# FM33LG0XX register map
File version: 1.0
CPU: SC000 r1p0, little endian, no MPU, no FPU, 3 interrupt priority bits
Registers are 32-bit, read-write, reset 0x0 unless marked. A register's access mark holds for its fields unless they carry their own. Offsets are from the block's base; [hi:lo] are bit positions; {n}, {i} and the like mark numbered series.

## DAC — DAC module information
Base 0x40019800
0x00 CR1 — DAC Control Register
  [0] EN — EN field description
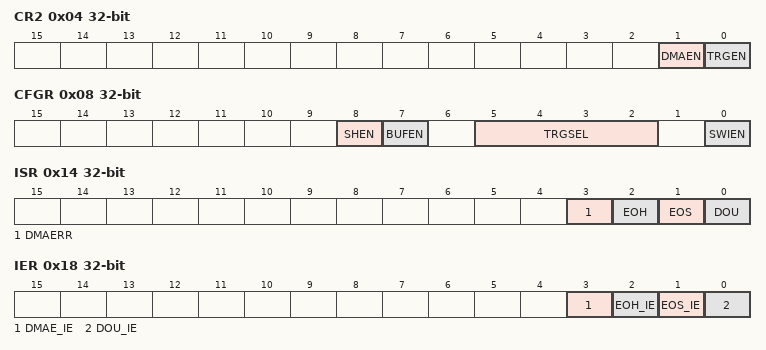
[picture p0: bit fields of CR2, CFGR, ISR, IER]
0x04 CR2 — DAC Control Register
  [1] DMAEN — DMAEN field description
  [0] TRGEN — TRGEN field description
0x08 CFGR — DAC Config Register
  [8] SHEN — SHEN field description
  [7] BUFEN — BUFEN field description
  [5:2] TRGSEL — TRGSEL field description
  [0] SWIEN — SWIEN field description
0x0C SWTRGR wo — DAC Software Trigger Register
  [0] SWTRIG — SWTRIG field description
0x10 DHR — DAC Data Holding Register
  [11:0] DHR — DHR field description
0x14 ISR — DAC Interrupt Status Register
  [3] DMAERR — DMAERR field description
  [2] EOH — EOH field description
  [1] EOS — EOS field description
  [0] DOU — DOU field description
0x18 IER — DAC Interrupt Enable Register
  [3] DMAE_IE — DMAE_IE field description
  [2] EOH_IE — EOH_IE field description
  [1] EOS_IE — EOS_IE field description
  [0] DOU_IE — DOU_IE field description
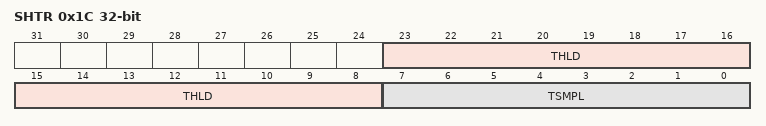
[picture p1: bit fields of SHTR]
0x1C SHTR — DAC Sample Hold Time Register
  [23:8] THLD — THLD field description
  [7:0] TSMPL — TSMPL field description

## PGL — PGL module information
Base 0x40016C00
0x00 CR — PGL Control Register
  [3:0] LUTEN — LUTEN field description
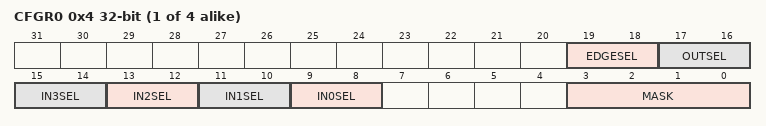
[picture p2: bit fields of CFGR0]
{0x4+4i} CFGR{i} (i=0..3) — PGL Config Register{i}
  [19:18] EDGESEL — EDGESEL field description
  [17:16] OUTSEL — OUTSEL field description
  [2n+9:2n+8] IN{n}SEL (n=0..3) — IN{n}SEL field description
  [3:0] MASK — MASK field description
0x14 IER — PGL Interrupt Enable Register
  [3:0] LUTIE — LUTIE field description
0x18 ISR — PGL Interrupt Status Register
  [3:0] LUTIF — LUTIF field description
{0x1C+4i} LUT{i} (i=0..3) — Look Up Table{i}
  [15:0] TRUTH — TRUTH field description

## GPIOA — GPIOA module information
Base 0x40000C00
Same registers: GPIOB 0x40000C40, GPIOC 0x40000C80, GPIOD 0x40000CC0, GPIOE 0x40000D00
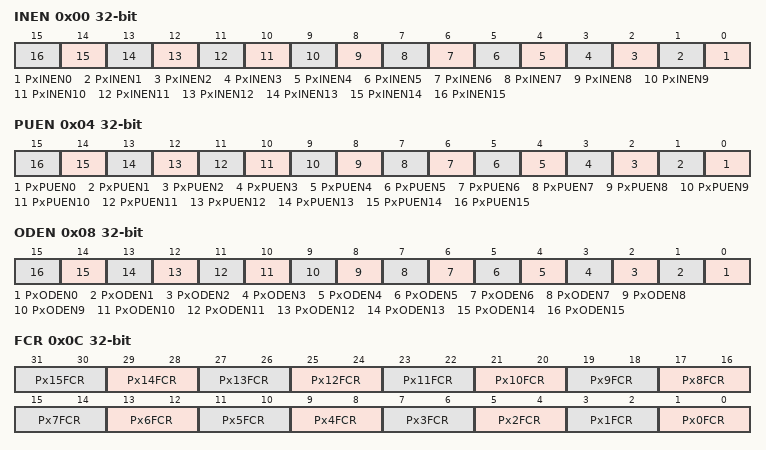
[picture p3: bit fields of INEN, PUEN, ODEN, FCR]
0x00 INEN — GPIOA Input Enable Register
  [n] PxINEN{n} (n=0..15) — PxINEN{n} field description
0x04 PUEN — GPIOA Pull-Up Enable Register
  [n] PxPUEN{n} (n=0..15) — PxPUEN{n} field description
0x08 ODEN — GPIOA Open-Drain Enable Register
  [n] PxODEN{n} (n=0..15) — PxODEN{n} field description
0x0C FCR — GPIOA Function Control Register
  [2n+1:2n] Px{n}FCR (n=0..15) — Px{n}FCR field description
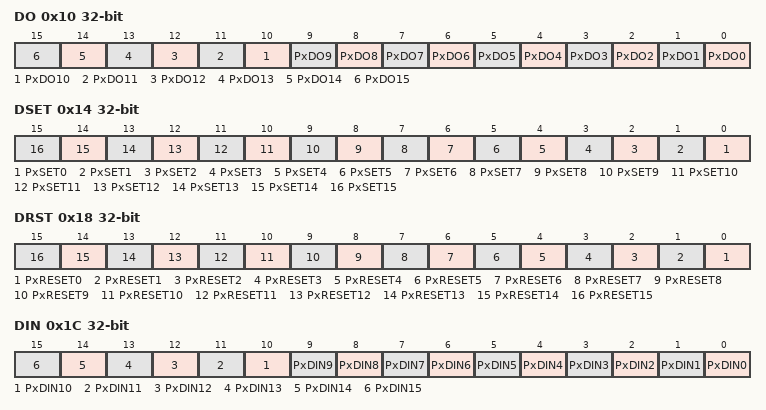
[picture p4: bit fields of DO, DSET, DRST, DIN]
0x10 DO — GPIOA Data Output Register
  [n] PxDO{n} (n=0..15) — PxDO{n} field description
0x14 DSET wo — GPIOA Data Set Register
  [n] PxSET{n} (n=0..15) — PxSET{n} field description
0x18 DRST wo — GPIOA Data Reset Register
  [n] PxRESET{n} (n=0..15) — PxRESET{n} field description
0x1C DIN ro — GPIOA Data Input Register
  [n] PxDIN{n} (n=0..15) — PxDIN{n} field description
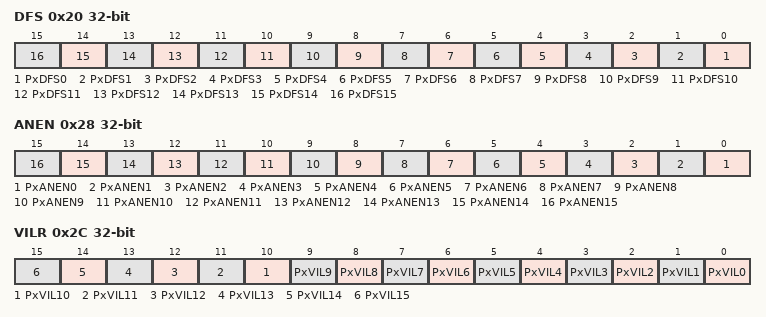
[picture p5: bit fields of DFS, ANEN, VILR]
0x20 DFS — GPIOA Digital Function Select
  [n] PxDFS{n} (n=0..15) — PxDFS{n} field description
0x28 ANEN — GPIOA Analog channel Enable Register
  [n] PxANEN{n} (n=0..15) — PxANEN{n} field description
0x2C VILR — GPIOA Voltage Input Low Register
  [n] PxVIL{n} (n=0..15) — PxVIL{n} field description

## GPIO — GPIO module information
Base 0x40000DC0
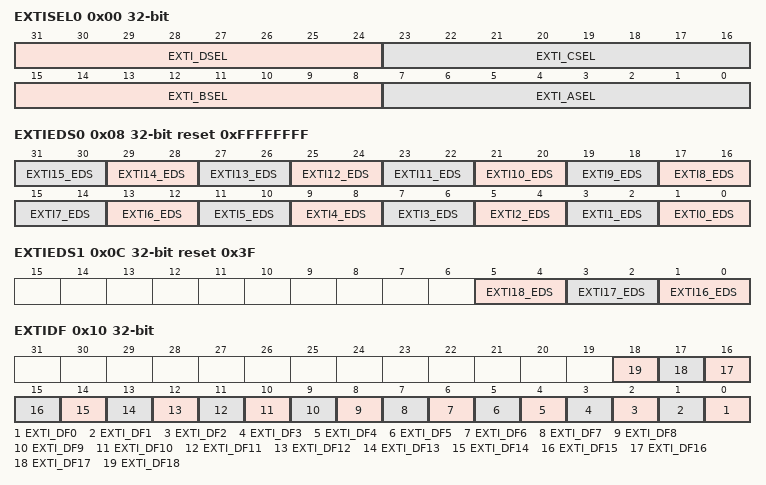
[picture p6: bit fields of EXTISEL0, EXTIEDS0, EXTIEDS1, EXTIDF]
0x00 EXTISEL0 — External Interrupt Input Select Register0
  [31:24] EXTI_DSEL — EXTI_DSEL field description
  [23:16] EXTI_CSEL — EXTI_CSEL field description
  [15:8] EXTI_BSEL — EXTI_BSEL field description
  [7:0] EXTI_ASEL — EXTI_ASEL field description
0x04 EXTISEL1 — External Interrupt Input Select Register1
  [7:0] EXTI_ESEL — EXTI_ESEL field description
0x08 EXTIEDS0 reset 0xFFFFFFFF — External Interrupt Edge Select and Enable Register0
  [2n+1:2n] EXTI{n}_EDS (n=0..15) — EXTI{n}_EDS field description
0x0C EXTIEDS1 reset 0x3F — External Interrupt Edge Select and Enable Register1
  [5:4] EXTI18_EDS — EXTI18_EDS field description
  [3:2] EXTI17_EDS — EXTI17_EDS field description
  [1:0] EXTI16_EDS — EXTI16_EDS field description
0x10 EXTIDF — External Interrupt Digital Filter Register
  [n] EXTI_DF{n} (n=0..18) — EXTI_DF{n} field description
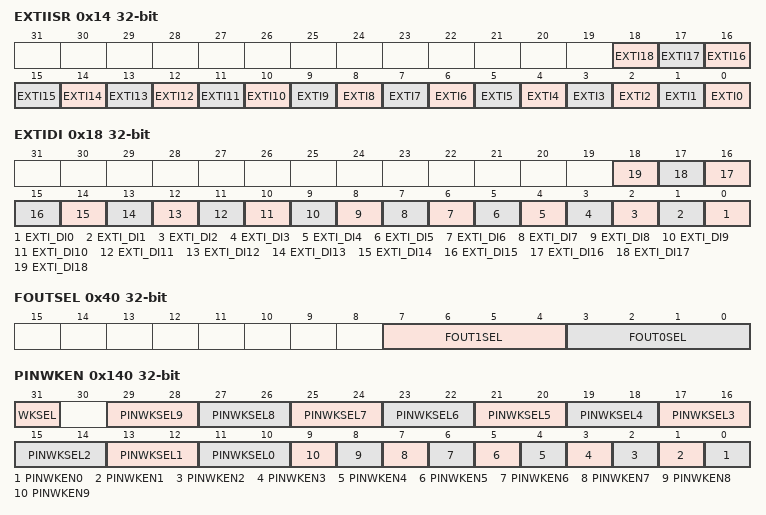
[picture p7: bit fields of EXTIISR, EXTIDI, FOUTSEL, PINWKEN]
0x14 EXTIISR — External Interrupt and Status Register
  [n] EXTI{n} (n=0..18) — EXTI{n} field description
0x18 EXTIDI ro — External Interrupt Data Input Register
  [n] EXTI_DI{n} (n=0..18) — EXTI_DI{n} field description
0x40 FOUTSEL — Frequency Output Select Register
  [7:4] FOUT1SEL — FOUT1SEL field description
  [3:0] FOUT0SEL — FOUT0SEL field description
0x140 PINWKEN — Wakeup Enable Register
  [31] WKSEL — WKSEL field description
  [2n+11:2n+10] PINWKSEL{n} (n=0..9) — PINWKSEL{n} field description
  [n] PINWKEN{n} (n=0..9) — PINWKEN{n} field description

## DBG — DBG module information
Base 0x40000000
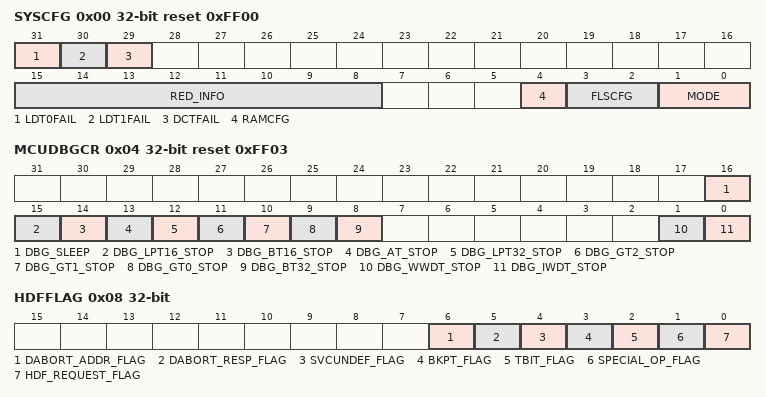
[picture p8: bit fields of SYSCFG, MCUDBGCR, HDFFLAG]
0x00 SYSCFG ro reset 0xFF00
  [31] LDT0FAIL — LDT0FAIL field description
  [30] LDT1FAIL — LDT1FAIL field description
  [29] DCTFAIL — DCTFAIL field description
  [15:8] RED_INFO — RED_INFO field description
  [4] RAMCFG — RAMCFG field description
  [3:2] FLSCFG — FLSCFG field description
  [1:0] MODE — MODE field description
0x04 MCUDBGCR reset 0xFF03
  [16] DBG_SLEEP — DBG_SLEEP field description
  [15] DBG_LPT16_STOP — DBG_LPT16_STOP field description
  [14] DBG_BT16_STOP — DBG_BT16_STOP field description
  [13] DBG_AT_STOP — DBG_AT_STOP field description
  [12] DBG_LPT32_STOP — DBG_LPT32_STOP field description
  [11] DBG_GT2_STOP — DBG_GT2_STOP field description
  [10] DBG_GT1_STOP — DBG_GT1_STOP field description
  [9] DBG_GT0_STOP — DBG_GT0_STOP field description
  [8] DBG_BT32_STOP — DBG_BT32_STOP field description
  [1] DBG_WWDT_STOP — DBG_WWDT_STOP field description
  [0] DBG_IWDT_STOP — DBG_IWDT_STOP field description
0x08 HDFFLAG
  [6] DABORT_ADDR_FLAG — DABORT_ADDR_FLAG field description
  [5] DABORT_RESP_FLAG — DABORT_RESP_FLAG field description
  [4] SVCUNDEF_FLAG — SVCUNDEF_FLAG field description
  [3] BKPT_FLAG — BKPT_FLAG field description
  [2] TBIT_FLAG — TBIT_FLAG field description
  [1] SPECIAL_OP_FLAG — SPECIAL_OP_FLAG field description
  [0] HDF_REQUEST_FLAG — HDF_REQUEST_FLAG field description
